# apollo3 register map
Vendor: Ambiq Micro; Series: Apollo; File version: 1.0
CPU: CM4 r1p0, little endian, MPU, FPU, 3 interrupt priority bits
Registers are 32-bit, read-write, reset 0x0 unless marked. A register's access mark holds for its fields unless they carry their own. Offsets are from the block's base; [hi:lo] are bit positions; {n}, {i} and the like mark numbered series; 'fields as' and 'values as' point back to an identical list.

## MSPI — Multibit SPI Master
Base 0x50014000
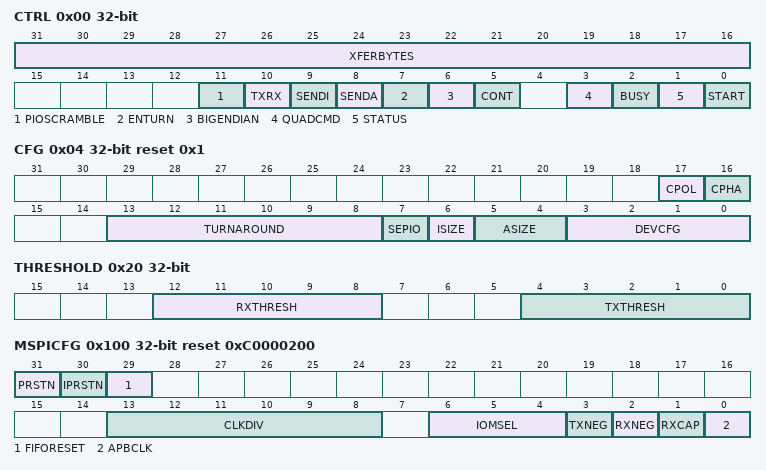
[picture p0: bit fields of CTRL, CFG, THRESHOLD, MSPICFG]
0x00 CTRL — MSPI PIO Transfer Control/Status Register
  [31:16] XFERBYTES — Number of bytes to transmit or receive (based on TXRX bit)
  [11] PIOSCRAMBLE — Enables data scrambling for PIO opertions. This should only be used for data operations and never for commands to a device.
  [10] TXRX — 1 Indicates a TX operation, 0 indicates an RX operation of XFERBYTES
  [9] SENDI — Indicates whether an instruction phase should be sent (see INSTR field and ISIZE field in CFG register)
  [8] SENDA — Indicates whether an address phase should be sent (see ADDR register and ASIZE field in CFG register)
  [7] ENTURN — Indicates whether TX->RX turnaround cycles should be enabled for this operation (see TURNAROUND field in CFG register).
  [6] BIGENDIAN — 1 indicates data in FIFO is in big endian format (MSB first); 0 indicates little endian data (default, LSB first).
  [5] CONT — Continuation transfer. When 1, indicates that the MSPI will hold CE low after the transaction completes. This is included for compatibility with IOM module since the MSPI transfer module can handle most cases in a single transfer. NOTE: CONT functionality only works with CLKDIV=2 (24 MHz).
  [3] QUADCMD — Flag indicating that the operation is a command that should be replicated to both devices in paired QUAD mode. This is typically only used when reading/writing configuration registers in paired flash devices (do not set for memory transfers).
  [2] BUSY — Command status: 1 indicates controller is busy (command in progress)
  [1] STATUS — Command status: 1 indicates command has completed. Cleared by writing 1 to this bit or starting a new transfer.
  [0] START — Write to 1 to initiate a PIO transaction on the bus (typically the entire register should be written at once with this bit set).
0x04 CFG reset 0x1 — MSPI Transfer Configuration Register
  [17] CPOL — Serial clock polarity.
    0=LOW (Clock inactive state is low. value.); 1=HIGH (Clock inactive state is high. value.)
  [16] CPHA — Serial clock phase.
    0=MIDDLE (Clock toggles in middle of data bit. value.); 1=START (Clock toggles at start of data bit. value.)
  [13:8] TURNAROUND — Number of turnaound cycles (for TX->RX transitions). Qualified by ENTURN or XIPENTURN bit field.
  [7] SEPIO — Separate IO configuration. This bit should be set when the target device has separate MOSI and MISO pins. Respective IN/OUT bits below should be set to map pins.
  [6] ISIZE — Instruction Size enum name = I8 value = 0x0 desc = Instruction is 1 byte enum name = I16 value = 0x1 desc = Instruction is 2 bytes
  [5:4] ASIZE — Address Size. Address bytes to send from ADDR register name = A1 value = 0x0 desc = Send one address byte enum name = A2 value = 0x1 desc = Send two address bytes enum name = A3 value = 0x2 desc = Send three address bytes enum name = A4 value = 0x3 desc = Send four address bytes
  [3:0] DEVCFG — Flash configuration for XIP and AUTO DMA operations. Controls value for SER (Slave Enable) for XIP operations and address generation for DMA/XIP modes. Also used to configure SPIFRF (frame format).
    1=SERIAL0 (Single bit SPI flash on chip select 0 value.); 2=SERIAL1 (Single bit SPI flash on chip select 1 value.); 5=DUAL0 (Dual SPI flash on chip select 0 value.); 6=DUAL1 (Dual bit SPI flash on chip select 1 value.); 9=QUAD0 (Quad SPI flash on chip select 0 value.); 10=QUAD1 (Quad SPI flash on chip select 1 value.); 13=OCTAL0 (Octal SPI flash on chip select 0 value.); 14=OCTAL1 (Octal SPI flash on chip select 1 value.); 15=QUADPAIRED (Dual Quad SPI flash on chip selects 0/1. value.); 3=QUADPAIRED_SERIAL (Dual Quad SPI flash on chip selects 0/1, but transmit in serial mode for initialization operations value.)
0x08 ADDR — MSPI Transfer Address Register
  [31:0] ADDR — Optional Address field to send (after optional instruction field) - qualified by ASIZE in CMD register. NOTE: This register is aliased to DMADEVADDR.
0x0C INSTR — MSPI Transfer Instruction
  [15:0] INSTR — Optional Instruction field to send (1st byte) - qualified by ISEND/ISIZE
0x10 TXFIFO — TX Data FIFO
  [31:0] TXFIFO — Data to be transmitted. Data should normall be aligned to the LSB (pad the upper bits with zeros) unless BIGENDIAN is set.
0x14 RXFIFO — RX Data FIFO
  [31:0] RXFIFO — Receive data. Data is aligned to the LSB (padded zeros on upper bits) unless BIGENDIAN is set.
0x18 TXENTRIES — TX FIFO Entries
  [4:0] TXENTRIES — Number of 32-bit words/entries in TX FIFO
0x1C RXENTRIES — RX FIFO Entries
  [4:0] RXENTRIES — Number of 32-bit words/entries in RX FIFO
0x20 THRESHOLD — TX/RX FIFO Threshhold Levels
  [12:8] RXTHRESH — Number of entries in TX FIFO that cause RXE interrupt
  [4:0] TXTHRESH — Number of entries in TX FIFO that cause TXF interrupt
0x100 MSPICFG reset 0xC0000200 — MSPI Module Configuration
  [31] PRSTN — Peripheral reset. Master reset to the entire MSPI module (DMA, XIP, and transfer state machines). 1=normal operation, 0=in reset.
  [30] IPRSTN — IP block reset. Write to 0 to put the transfer module in reset or 1 for normal operation. This may be required after error conditions to clear the transfer on the bus.
  [29] FIFORESET — Reset MSPI FIFO (active high). 1=reset FIFO, 0=normal operation. May be used to manually flush the FIFO in error handling.
  [13:8] CLKDIV — Clock Divider. Allows dividing 48 MHz base clock by integer multiples. Enumerations are provided for common frequency, but any integer divide from 48 MHz is allowed. Odd divide ratios will result in a 33/66 percent duty cycle with a long low clock pulse (to allow longer round-trip for read data).
    2=CLK24 (24 MHz MSPI clock value.); 4=CLK12 (12 MHz MSPI clock value.); 8=CLK6 (6 MHz MSPI clock value.); 16=CLK3 (3 MHz MSPI clock value.); 32=CLK1_5 (1.5 MHz MSPI clock value.)
  [6:4] IOMSEL — Selects which IOM is selected for CQ handshake status.
    {v}=IOM{v} (ERROR: desc VALUE MISSING value.) (v=0..5); 7=DISABLED (No IOM selected. Signals always zero. value.)
  [3] TXNEG — Launches TX data a half clock cycle (~10ns) early. This should normally be programmed to zero (NORMAL).
    0=NORMAL (TX launched from posedge internal clock value.); 1=NEGEDGE (TX data launched from negedge of internal clock value.)
  [2] RXNEG — Adjusts the RX capture phase to the negedge of the 48MHz internal clock (~10ns early). For normal operation, it is expected that RXNEG will be set to 0.
    0=NORMAL (RX data sampled on posedge of internal clock value.); 1=NEGEDGE (RX data sampled on negedge of internal clock value.)
  [1] RXCAP — Controls RX data capture phase. A setting of 0 (NORMAL) captures read data at the normal capture point relative to the internal clock launch point. However, to accomodate chip/pad/board delays, a setting of RXCAP of 1 is expected to be used to align the capture point with the return data window. This bit is used in conjunction with RXNEG to provide 4 unique capture points, all about 10ns apart.
    0=NORMAL (RX Capture phase aligns with CPHA setting value.); 1=DELAY (RX Capture phase is delayed from CPHA setting by one clock edge value.)
  [0] APBCLK — Enable continuous APB clock. For power-efficient operation, APBCLK should be set to 0.
    0=DIS (Disable continuous clock. value.); 1=EN (Enable continuous clock. value.)
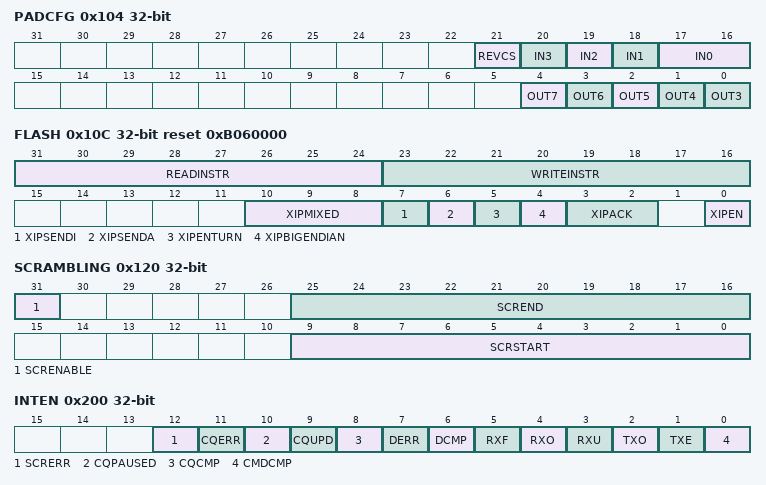
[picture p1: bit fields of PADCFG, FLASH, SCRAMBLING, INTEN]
0x104 PADCFG — MSPI Output Pad Configuration
  [21] REVCS — Reverse CS connections. Allows CS1 to be associated with lower data lanes and CS0 to be associated with upper data lines
  [20] IN3 — Data Input pad 3 pin muxing: 0=pad[3] 1=pad[7]
  [19] IN2 — Data Input pad 2 pin muxing: 0=pad[2] 1=pad[6]
  [18] IN1 — Data Input pad 1 pin muxing: 0=pad[1] 1=pad[5]
  [17:16] IN0 — Data Input pad 0 pin muxing: 0=pad[0] 1=pad[4] 2=pad[1] 3=pad[5]
  [n-3] OUT{n} (n=4..7) — Output pad {n} configuration. 0=data[{n}] 1=data[{n-4}]
  [0] OUT3 — Output pad 3 configuration. 0=data[3] 1=CLK
0x108 PADOUTEN — MSPI Output Enable Pad Configuration
  [8:0] OUTEN — Output pad enable configuration. Indicates which pads should be driven. Bits [3:0] are Quad0 data, [7:4] are Quad1 data, and [8] is clock.
    0x10F=QUAD0 (Quad0 (4 data + 1 clock) value.); 0x1F0=QUAD1 (Quad1 (4 data + 1 clock) value.); 0x1FF=OCTAL (Octal (8 data + 1 clock) value.); 0x103=SERIAL0 (Serial (2 data + 1 clock) value.)
0x10C FLASH reset 0xB060000 — Configuration for XIP/DMA support of SPI flash modules.
  [31:24] READINSTR — Read command sent to flash for DMA/XIP operations
  [23:16] WRITEINSTR — Write command sent for DMA operations
  [10:8] XIPMIXED — Reserved. Set to 0x0
  [7] XIPSENDI — Indicates whether XIP/AUTO DMA operations should send an instruction (see READINSTR field and ISIZE field in CFG)
  [6] XIPSENDA — Indicates whether XIP/AUTO DMA operations should send an an address phase (see DMADEVADDR register and ASIZE field in CFG)
  [5] XIPENTURN — Indicates whether XIP/AUTO DMA operations should enable TX->RX turnaround cycles
  [4] XIPBIGENDIAN — Indicates whether XIP/AUTO DMA data transfers are in big or little endian format
  [3:2] XIPACK — Controls transmission of Micron XIP acknowledge cycles (Micron Flash devices only)
    0=NOACK (No acknowledege sent. Data IOs are tristated the first turnaround cycle value.); 2=ACK (Positive acknowledege sent. Data IOs are driven to 0 the first turnaround cycle to acknowledge XIP mode value.); 3=TERMINATE (Negative acknowledege sent. Data IOs are driven to 1 the first turnaround cycle to terminate XIP mode. XIPSENDI should be reenabled for the next transfer value.)
  [0] XIPEN — Enable the XIP (eXecute In Place) function which effectively enables the address decoding of the MSPI device in the flash/cache address space at address 0x04000000-0x07FFFFFF.
0x120 SCRAMBLING — External Flash Scrambling Controls
  [31] SCRENABLE — Enables Data Scrambling Region. When 1 reads and writes to the range will be scrambled. When 0, data will be read/written unmodified. Address range is specified in 64K granularity and the START/END ranges are included within the range.
  [25:16] SCREND — Scrambling region end address [25:16] (64K block granularity). The END block is the LAST block included in the scrambled address range.
  [9:0] SCRSTART — Scrambling region start address [25:16] (64K block granularity). The START block is the FIRST block included in the scrambled address range.
0x200 INTEN — MSPI Master Interrupts: Enable
  [12] SCRERR — Scrambling Alignment Error. Scrambling operations must be aligned to word (4-byte) start address.
  [11] CQERR — Command Queue Error Interrupt
  [10] CQPAUSED — Command Queue is Paused.
  [9] CQUPD — Command Queue Update Interrupt. Issued whenever the CQ performs an operation where address bit[0] is set. Useful for triggering CURIDX interrupts.
  [8] CQCMP — Command Queue Complete Interrupt
  [7] DERR — DMA Error Interrupt
  [6] DCMP — DMA Complete Interrupt
  [5] RXF — Receive FIFO full
  [4] RXO — Receive FIFO overflow (cannot happen in MSPI design -- MSPI bus pins will stall)
  [3] RXU — Receive FIFO underflow (only occurs when SW reads from an empty FIFO)
  [2] TXO — Transmit FIFO Overflow (only occurs when SW writes to a full FIFO).
  [1] TXE — Transmit FIFO empty.
  [0] CMDCMP — Transfer complete. Note that DMA and CQ operations are layered, so CMDCMP, DCMP, and CQ* can all be signalled simultaneously
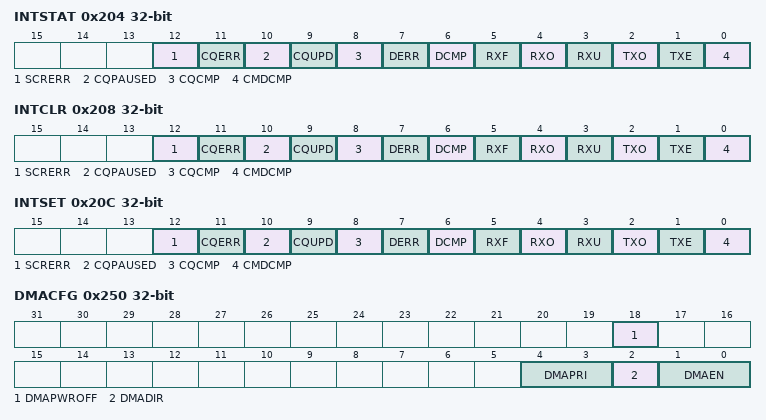
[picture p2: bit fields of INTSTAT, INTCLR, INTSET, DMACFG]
0x204 INTSTAT — MSPI Master Interrupts: Status
  fields as INTEN
0x208 INTCLR — MSPI Master Interrupts: Clear
  fields as INTEN
0x20C INTSET — MSPI Master Interrupts: Set
  fields as INTEN
0x250 DMACFG — DMA Configuration Register
  [18] DMAPWROFF — Power off MSPI domain upon completion of DMA operation.
  [4:3] DMAPRI — Sets the Priority of the DMA request
    0=LOW (Low Priority (service as best effort) value.); 1=HIGH (High Priority (service immediately) value.); 2=AUTO (Auto Priority (priority raised once TX FIFO empties or RX FIFO fills) value.)
  [2] DMADIR — Direction
    0=P2M (Peripheral to Memory (SRAM) transaction value.); 1=M2P (Memory to Peripheral transaction value.)
  [1:0] DMAEN — DMA Enable. Setting this bit to EN will start the DMA operation
    0=DIS (Disable DMA Function value.); 3=EN (Enable HW controlled DMA Function to manage DMA to flash devices. HW will automatically handle issuance of instruction/address bytes based on settings in the FLASH register. value.)
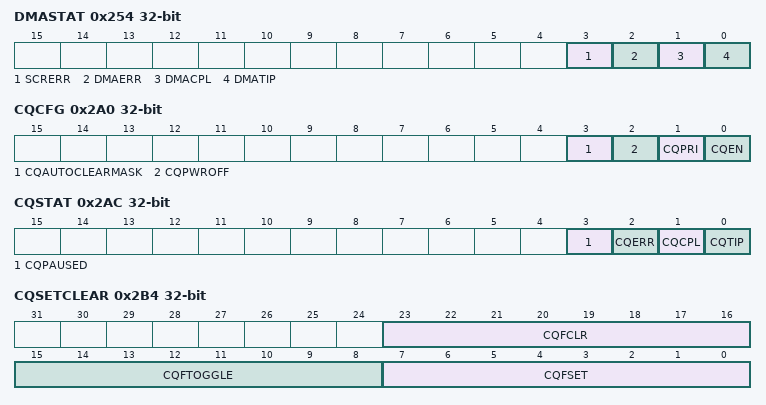
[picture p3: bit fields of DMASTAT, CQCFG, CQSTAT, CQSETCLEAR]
0x254 DMASTAT — DMA Status Register
  [3] SCRERR — Scrambling Access Alignment Error. This active high bit signals that a scrambling operation was specified for a non-word aligned DEVADDR.
  [2] DMAERR — DMA Error. This active high bit signals that an error was encountered during the DMA operation.
  [1] DMACPL — DMA Transfer Complete. This signals the end of the DMA operation.
  [0] DMATIP — DMA Transfer In Progress indicator. 1 will indicate that a DMA transfer is active. The DMA transfer may be waiting on data, transferring data, or waiting for priority. All of these will be indicated with a 1. A 0 will indicate that the DMA is fully complete and no further transactions will be done.
0x258 DMATARGADDR — DMA Target Address Register
  [31:0] TARGADDR — Target byte address for source of DMA (either read or write). In cases of non-word aligned addresses, the DMA logic will take care for ensuring only the target bytes are read/written.
0x25C DMADEVADDR — DMA Device Address Register
  [31:0] DEVADDR — SPI Device address for automated DMA transactions (both read and write).
0x260 DMATOTCOUNT — DMA Total Transfer Count
  [15:0] TOTCOUNT — Total Transfer Count in bytes.
0x264 DMABCOUNT — DMA BYTE Transfer Count
  [7:0] BCOUNT — Burst transfer size in bytes. This is the number of bytes transferred when a FIFO trigger event occurs. Recommended values are 16 or 32.
0x278 DMATHRESH reset 0x8 — DMA Transmit Trigger Threshhold
  [3:0] DMATHRESH — DMA transfer FIFO level trigger. For read operations, DMA is triggered when the FIFO level is greater than this value. For write operations, DMA is triggered when the FIFO level is less than this level. Each DMA operation will consist of BCOUNT bytes.
0x2A0 CQCFG — Command Queue Configuration Register
  [3] CQAUTOCLEARMASK — Eanble clear of CQMASK after each pause operation. This may be useful when using software flags to pause CQ.
  [2] CQPWROFF — Power off MSPI domain upon completion of DMA operation.
  [1] CQPRI — Sets the Priority of the command queue dma request
    0=LOW (Low Priority (service as best effort) value.); 1=HIGH (High Priority (service immediately) value.)
  [0] CQEN — Command queue enable. When set, will enable the processing of the command queue
    0=DIS (Disable CQ Function value.); 1=EN (Enable CQ Function value.)
0x2A8 CQADDR — CQ Target Read Address Register
  [28:0] CQADDR — Address of command queue buffer in SRAM or flash. The buffer address must be aligned to a word boundary.
0x2AC CQSTAT — Command Queue Status Register
  [3] CQPAUSED — Command queue is currently paused status.
  [2] CQERR — Command queue processing Error. This active high bit signals that an error was encountered during the CQ operation.
  [1] CQCPL — Command queue operation Complete. This signals the end of the command queue operation.
  [0] CQTIP — Command queue Transfer In Progress indicator. 1 will indicate that a CQ transfer is active and this will remain active even when paused waiting for external event.
0x2B0 CQFLAGS — Command Queue Flag Register
  [15:0] CQFLAGS — Current flag status (read-only). Bits [7:0] are software controllable and bits [15:8] are hardware status.
    0x8000=STOP (CQ Stop Flag. When set, CQ processing will complete. value.); 0x4000=CQIDX (CQ Index Pointers (CURIDX/ENDIDX) match. value.); 0x800=DMACPL (DMA Complete Status (hardwired DMACPL bit in DMASTAT) value.); 0x400=CMDCPL (PIO Operation completed (STATUS bit in CTRL register) value.); 0x200=IOM1READY (IOM Buffer 1 Ready Status (from selected IOM). This status is the result of XOR'ing the IOM0START with the incoming status from the IOM. When high, MSPI can send to the buffer. value.); 0x100=IOM0READY (IOM Buffer 0 Ready Status (from selected IOM). This status is the result of XOR'ing the IOM0START with the incoming status from the IOM. When high, MSPI can send to the buffer. value.); 128=SWFLAG7 (Software flag 7. Can be used by software to start/pause operations value.); 64=SWFLAG6 (Software flag 6. Can be used by software to start/pause operatoins value.); 32=SWFLAG5 (Software flag 5. Can be used by software to start/pause operations value.); 16=SWFLAG4 (Software flag 4. Can be used by software to start/pause operatoins value.); 8=SWFLAG3 (Software flag 3. Can be used by software to start/pause operations value.); 4=SWFLAG2 (Software flag 2. Can be used by software to start/pause operatoins value.); 2=SWFLAG1 (Software flag 1. Can be used by software to start/pause operations value.); 1=SWFLAG0 (Software flag 0. Can be used by software to start/pause operatoins value.)
0x2B4 CQSETCLEAR — Command Queue Flag Set/Clear Register
  [23:16] CQFCLR — Clear CQFlag status bits.
  [15:8] CQFTOGGLE — Toggle CQFlag status bits
  [7:0] CQFSET — Set CQFlag status bits. Set has priority over clear if both are high.
0x2B8 CQPAUSE — Command Queue Pause Mask Register
  [15:0] CQMASK — CQ will pause processing until all specified events are satisfied.
    values as CQFLAGS.CQFLAGS
0x2C0 CQCURIDX — Command Queue Current Index
  [7:0] CQCURIDX — Can be used to indicate the current position of the command queue by having CQ operations write this field. A CQ hardware status flag indicates when CURIDX and ENDIDX are not equal, allowing SW to pause the CQ processing until the end index is updated.
0x2C4 CQENDIDX — Command Queue End Index
  [7:0] CQENDIDX — Can be used to indicate the end position of the command queue. A CQ hardware status bit indices when CURIDX != ENDIDX so that the CQ can be paused when it reaches the end pointer.
